# S6E2CCxJ register map
Vendor: Cypress; File version: 2.0
CPU: CM4 r0p1, little endian, MPU, FPU, 4 interrupt priority bits
Registers are 32-bit, read-write, reset 0x0 unless marked. A register's access mark holds for its fields unless they carry their own. Offsets are from the block's base; [hi:lo] are bit positions.

## USBETHERCLK — USB/Ethernet Clock
Base 0x40036000
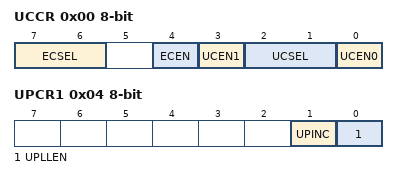
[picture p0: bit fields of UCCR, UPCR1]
0x00 UCCR 8-bit (reset mask 0x7F) — USB/Ethernet-PLL Clock Control Register
  [7:6] ECSEL — Ethernet clock selection bit
  [4] ECEN — Ethernet clock output enable bit
  [3] UCEN1 — USB1 clock output enable bit
  [2:1] UCSEL — USB1/0 clock selection bit
  [0] UCEN0 — USB0 clock output enable bit
0x04 UPCR1 8-bit — USB/Ethernet-PLL Control Register 1
  [1] UPINC — USB/Ethernet-PLL input clock selection bit
  [0] UPLLEN — USB/Ethernet-PLL oscillation enable bit
0x08 UPCR2 8-bit — USB/Ethernet-PLL Control Register 2
  [2:0] UPOWT — USB/Ethernet-PLL oscillation stabilization wait time setting bit
0x0C UPCR3 8-bit — USB/Ethernet-PLL Control Register 3
  [4:0] UPLLK — Frequency division ratio (K) setting bit of the USB/Ethernet-PLL clock
0x10 UPCR4 8-bit reset 0x3B — USB/Ethernet-PLL Control Register 4
  [6:0] UPLLN — Frequency division ratio (N) setting bit of the USB/Ethernet-PLL clock
0x14 UP_STR 8-bit ro — USB/Ethernet-PLL Status Register
  [0] UPRDY — USB/Ethernet-PLL oscillation stabilization bit
0x18 UPINT_ENR 8-bit — USB/Ethernet-PLL Interrupt Source Enable Register
  [0] UPCSE — USB/Ethernet-PLL oscillation stabilization wait complete interrupt enable bit
0x1C UPINT_CLR 8-bit wo — USB/Ethernet-PLL Interrupt Source Clear Register
  [0] UPCSC — USB/Ethernet-PLL oscillation stabilization interrupt source clear bit
0x20 UPINT_STR 8-bit ro — USB/Ethernet-PLL Interrupt Source Status Register
  [0] UPCSI — USB/Ethernet-PLL interrupt source status bit
0x24 UPCR5 8-bit reset 0x4 — USB/Ethernet-PLL Control Register 5
  [3:0] UPLLM — Frequency division ratio (M) setting bit of the USB/Ethernet-PLL clock
0x28 UPCR6 8-bit reset 0x2 — USB/Ethernet-PLL Setting Register 6
  [3:0] UBSR — CLKPLL division ratio setting bit
0x2C UPCR7 8-bit — USB/Ethernet-PLL Setting Register 7
  [0] EPLLEN — USB/Ethernet-PLL control bit in Timer mode
0x30 USBEN0 8-bit — USB0 Enable Register
  [0] USBEN0 — USB0 enable bit
0x34 USBEN1 8-bit — USB1 Enable Register
  [0] USBEN1 — USB1 enable bit

## CANPRES — CAN Prescaler Register
Base 0x40037000
0x00 CANPRE 8-bit reset 0xB — CAN Prescaler Register
  [3:0] CANPRE — CAN prescaler setting bits

## CRC — CRC Registers
Base 0x40039000
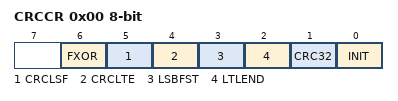
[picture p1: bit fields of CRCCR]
0x00 CRCCR 8-bit — CRC Control Register
  [6] FXOR — Initialization bit
  [5] CRCLSF — Final XOR control bit
  [4] CRCLTE — CRC result bit-order setting bit
  [3] LSBFST — CRC result byte-order setting bit
  [2] LTLEND — Bit-order setting bit
  [1] CRC32 — Byte-order setting bit
  [0] INIT — CRC mode selection bit
0x04 CRCINIT reset 0xFFFFFFFF — Initial Value Register
  [31:0] D — Initial value
0x08 CRCIN — Input Data Register
  [31:0] D — Input data
0x0C CRCR ro reset 0xFFFFFFFF — CRC Register
  [31:0] D — CRC Data

## WC — Watch Counter
Base 0x4003A000
0x00 WCRD 8-bit ro — Watch Counter Read Register
  [5:0] CTR — Counter read bits
0x01 WCRL 8-bit — Watch Counter Reload Register
  [5:0] RLC — Counter reload value setting bits
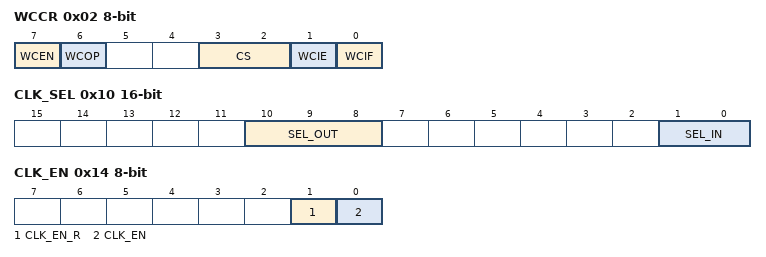
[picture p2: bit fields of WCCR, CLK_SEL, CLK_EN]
0x02 WCCR 8-bit — Watch Counter Control Register
  [7] WCEN — Watch counter operation enable bit
  [6] WCOP ro — Watch counter operating state flag
  [3:2] CS — Count clock select bits
  [1] WCIE — Interrupt request enable bit
  [0] WCIF — Interrupt request flag bit
0x10 CLK_SEL 16-bit — Clock Selection Register
  [10:8] SEL_OUT — Output clock selection bit
  [1:0] SEL_IN — Input clock selection bit
0x14 CLK_EN 8-bit — Division Clock Enable Register
  [1] CLK_EN_R — Division clock enable read bit
  [0] CLK_EN — Division clock enable bit

## LSCRP — Low-speed CR Prescaler
Base 0x4003C000
0x00 LCR_PRSLD 8-bit — Low-speed CR Prescaler Control Register
  [5:0] LCR_PRSLD — Low-speed CR Prescaler Load
